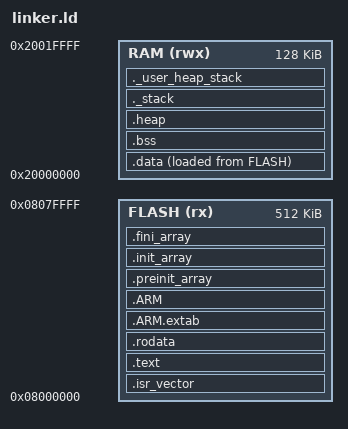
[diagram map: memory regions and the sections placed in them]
/*
 * linker.ld — Linker script for STM32G474RET6 (512 KB Flash, 128 KB SRAM)
 *
 * Author: jayis1
 * Copyright (C) 2026 jayis1. All rights reserved.
 * License: GPL-3.0
 */

ENTRY(Reset_Handler)

/* Memory regions */
MEMORY
{
    FLASH (rx)  : ORIGIN = 0x08000000, LENGTH = 512K
    RAM   (rwx) : ORIGIN = 0x20000000, LENGTH = 128K
}

/* Stack starts at top of RAM */
_estack = ORIGIN(RAM) + LENGTH(RAM);
_min_stack_size = 0x400;  /* 1 KB minimum stack */

SECTIONS
{
    /* Vector table — must be at the start of flash */
    .isr_vector :
    {
        . = ALIGN(4);
        KEEP(*(.isr_vector))
        . = ALIGN(4);
    } > FLASH

    /* Code */
    .text :
    {
        . = ALIGN(4);
        *(.text)
        *(.text*)
        *(.glue_7)
        *(.glue_7t)
        *(.eh_frame)
        KEEP(*(.init))
        KEEP(*(.fini))
        . = ALIGN(4);
        _etext = .;
    } > FLASH

    /* Read-only data */
    .rodata :
    {
        . = ALIGN(4);
        *(.rodata)
        *(.rodata*)
        . = ALIGN(4);
    } > FLASH

    /* ARM exception tables */
    .ARM.extab :
    {
        *(.ARM.extab* .gnu.linkonce.armextab.*)
    } > FLASH

    .ARM :
    {
        __exidx_start = .;
        *(.ARM.exidx*)
        __exidx_end = .;
    } > FLASH

    /* Pre-init array */
    .preinit_array :
    {
        PROVIDE_HIDDEN(__preinit_array_start = .);
        KEEP(*(.preinit_array*))
        PROVIDE_HIDDEN(__preinit_array_end = .);
    } > FLASH

    /* Init array (C++ constructors — not used in C but included for completeness) */
    .init_array :
    {
        PROVIDE_HIDDEN(__init_array_start = .);
        KEEP(*(SORT(.init_array.*)))
        KEEP(*(.init_array*))
        PROVIDE_HIDDEN(__init_array_end = .);
    } > FLASH

    /* Fini array */
    .fini_array :
    {
        PROVIDE_HIDDEN(__fini_array_start = .);
        KEEP(*(SORT(.fini_array.*)))
        KEEP(*(.fini_array*))
        PROVIDE_HIDDEN(__fini_array_end = .);
    } > FLASH

    /* Base address of .data in flash (for copy to RAM at startup) */
    _sidata = LOADADDR(.data);

    /* Initialized data (copied from flash to RAM at startup) */
    .data :
    {
        . = ALIGN(4);
        _sdata = .;
        *(.data)
        *(.data*)
        . = ALIGN(4);
        _edata = .;
    } > RAM AT > FLASH

    /* Zero-initialized data (BSS) — cleared at startup */
    .bss :
    {
        . = ALIGN(4);
        _sbss = .;
        __bss_start__ = .;
        *(.bss)
        *(.bss*)
        *(COMMON)
        . = ALIGN(4);
        _ebss = .;
        __bss_end__ = .;
    } > RAM

    /* Heap (grows upward from end of BSS) */
    .heap :
    {
        . = ALIGN(8);
        _sheap = .;
        . = . + 0x1000;  /* 4 KB heap */
        . = ALIGN(8);
        _eheap = .;
    } > RAM

    /* Stack section (for checking — actual stack uses _estack) */
    ._stack :
    {
        . = ALIGN(8);
        . = . + _min_stack_size;
        . = ALIGN(8);
    } > RAM

    /* Check that stack + heap + BSS fit in RAM */
    ._user_heap_stack (NOLOAD) :
    {
        . = ALIGN(8);
        PROVIDE(end = .);
        PROVIDE(_end = .);
        . = . + 0x400;
        . = ALIGN(8);
    } > RAM

    /* Discard unneeded sections */
    /DISCARD/ :
    {
        *(.ARM.attributes)
        *(.comment)
    }
}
